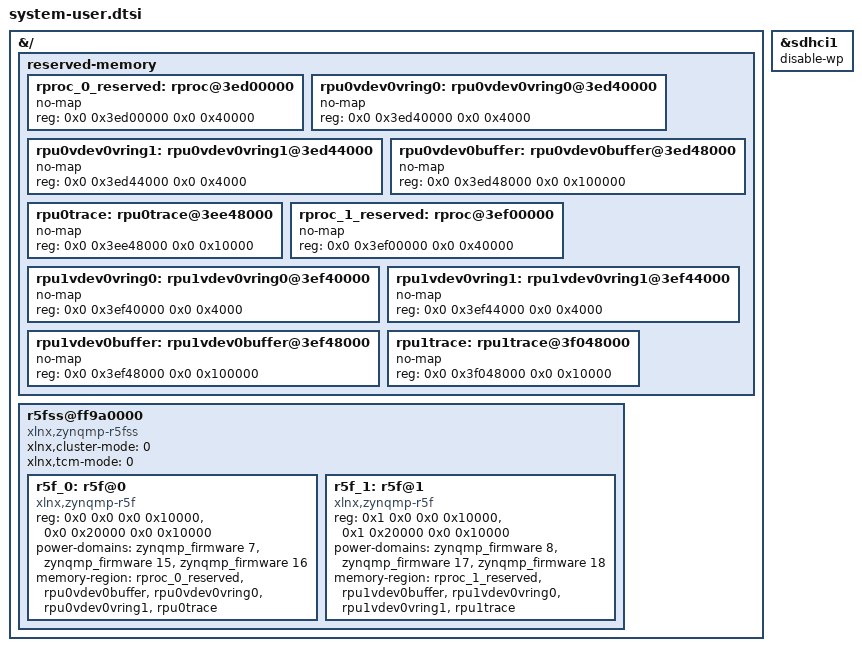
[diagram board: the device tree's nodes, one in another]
/* SEE: build/linux/tmp/work-shared/genesys_zu-5ev/kernel-source
/* SEE: kernel-source/Documentation/devicetree/bindings/remoteproc/xlnx,zynqmp-r5fss.yaml */
/* SEE: kernel-source/Documentation/devicetree/bindings/mailbox/xlnx,zynqmp-ipi-mailbox.yaml */

/* SEE: src/resource_table.c */

&{/} {
	reserved-memory {
		#address-cells = <2>;
		#size-cells = <2>;
		ranges;

		rproc_0_reserved: rproc@3ed00000 {
			no-map;
			reg = <0x0 0x3ed00000 0x0 0x40000>;  /* 256KiB */
		};

		rpu0vdev0vring0: rpu0vdev0vring0@3ed40000 {
			no-map;
			reg = <0x0 0x3ed40000 0x0 0x4000>;  /* 16KiB */
		};

		rpu0vdev0vring1: rpu0vdev0vring1@3ed44000 {
			no-map;
			reg = <0x0 0x3ed44000 0x0 0x4000>;  /* 16KiB */
		};

		rpu0vdev0buffer: rpu0vdev0buffer@3ed48000 {
			no-map;
			reg = <0x0 0x3ed48000 0x0 0x100000>;  /* 1MiB */
		};

		rpu0trace: rpu0trace@3ee48000 {
			no-map;
			reg = <0x0 0x3ee48000 0x0 0x10000>;  /* 64KiB */
		};

		rproc_1_reserved: rproc@3ef00000 {
			no-map;
			reg = <0x0 0x3ef00000 0x0 0x40000>;  /* 256KiB */
		};

		rpu1vdev0vring0: rpu1vdev0vring0@3ef40000 {
			no-map;
			reg = <0x0 0x3ef40000 0x0 0x4000>;  /* 16KiB */
		};

		rpu1vdev0vring1: rpu1vdev0vring1@3ef44000 {
			no-map;
			reg = <0x0 0x3ef44000 0x0 0x4000>;  /* 16KiB */
		};

		rpu1vdev0buffer: rpu1vdev0buffer@3ef48000 {
			no-map;
			reg = <0x0 0x3ef48000 0x0 0x100000>;  /* 1MiB */
		};

		rpu1trace: rpu1trace@3f048000 {
			no-map;
			reg = <0x0 0x3f048000 0x0 0x10000>;  /* 64KiB */
		};
	};

	r5fss@ff9a0000 {
		compatible = "xlnx,zynqmp-r5fss";
		xlnx,cluster-mode = <0>;
		xlnx,tcm-mode = <0>;

		#address-cells = <2>;
		#size-cells = <2>;

		ranges = <0x0 0x0 0x0 0xffe00000 0x0 0x10000>,      /* R5F0 ATCM */
		         <0x0 0x20000 0x0 0xffe20000 0x0 0x10000>,  /* R5F0 BTCM */
		         <0x1 0x0 0x0 0xffe90000 0x0 0x10000>,      /* R5F1 ATCM */
		         <0x1 0x20000 0x0 0xffeb0000 0x0 0x10000>;  /* R5F1 BTCM */

		r5f_0: r5f@0 {
			compatible = "xlnx,zynqmp-r5f";
			reg = <0x0 0x0 0x0 0x10000>,      /* ATCM - 64KB */
			      <0x0 0x20000 0x0 0x10000>;  /* BTCM - 64KB */
			reg-names = "atcm0", "btcm0";

			/* SEE: kernel-source/include/dt-bindings/power/xlnx-zynqmp-power.h */
			power-domains = <&zynqmp_firmware 7>,   /* PD_RPU_0 */
			                <&zynqmp_firmware 15>,  /* PD_R5_0_ATCM */
			                <&zynqmp_firmware 16>;  /* PD_R5_0_BTCM */

			memory-region = <&rproc_0_reserved>, <&rpu0vdev0buffer>,
			                <&rpu0vdev0vring0>, <&rpu0vdev0vring1>,
			                <&rpu0trace>;
		};

		r5f_1: r5f@1 {
			compatible = "xlnx,zynqmp-r5f";
			reg = <0x1 0x0 0x0 0x10000>,      /* ATCM - 64KB */
			      <0x1 0x20000 0x0 0x10000>;  /* BTCM - 64KB */
			reg-names = "atcm0", "btcm0";

			/* SEE: kernel-source/include/dt-bindings/power/xlnx-zynqmp-power.h */
			power-domains = <&zynqmp_firmware 8>,   /* PD_RPU_1 */
			                <&zynqmp_firmware 17>,  /* PD_R5_1_ATCM */
			                <&zynqmp_firmware 18>;  /* PD_R5_1_BTCM */

			memory-region = <&rproc_1_reserved>, <&rpu1vdev0buffer>,
			                <&rpu1vdev0vring0>, <&rpu1vdev0vring1>,
			                <&rpu1trace>;
		};
	};
};

&sdhci1 {
	disable-wp;
};
